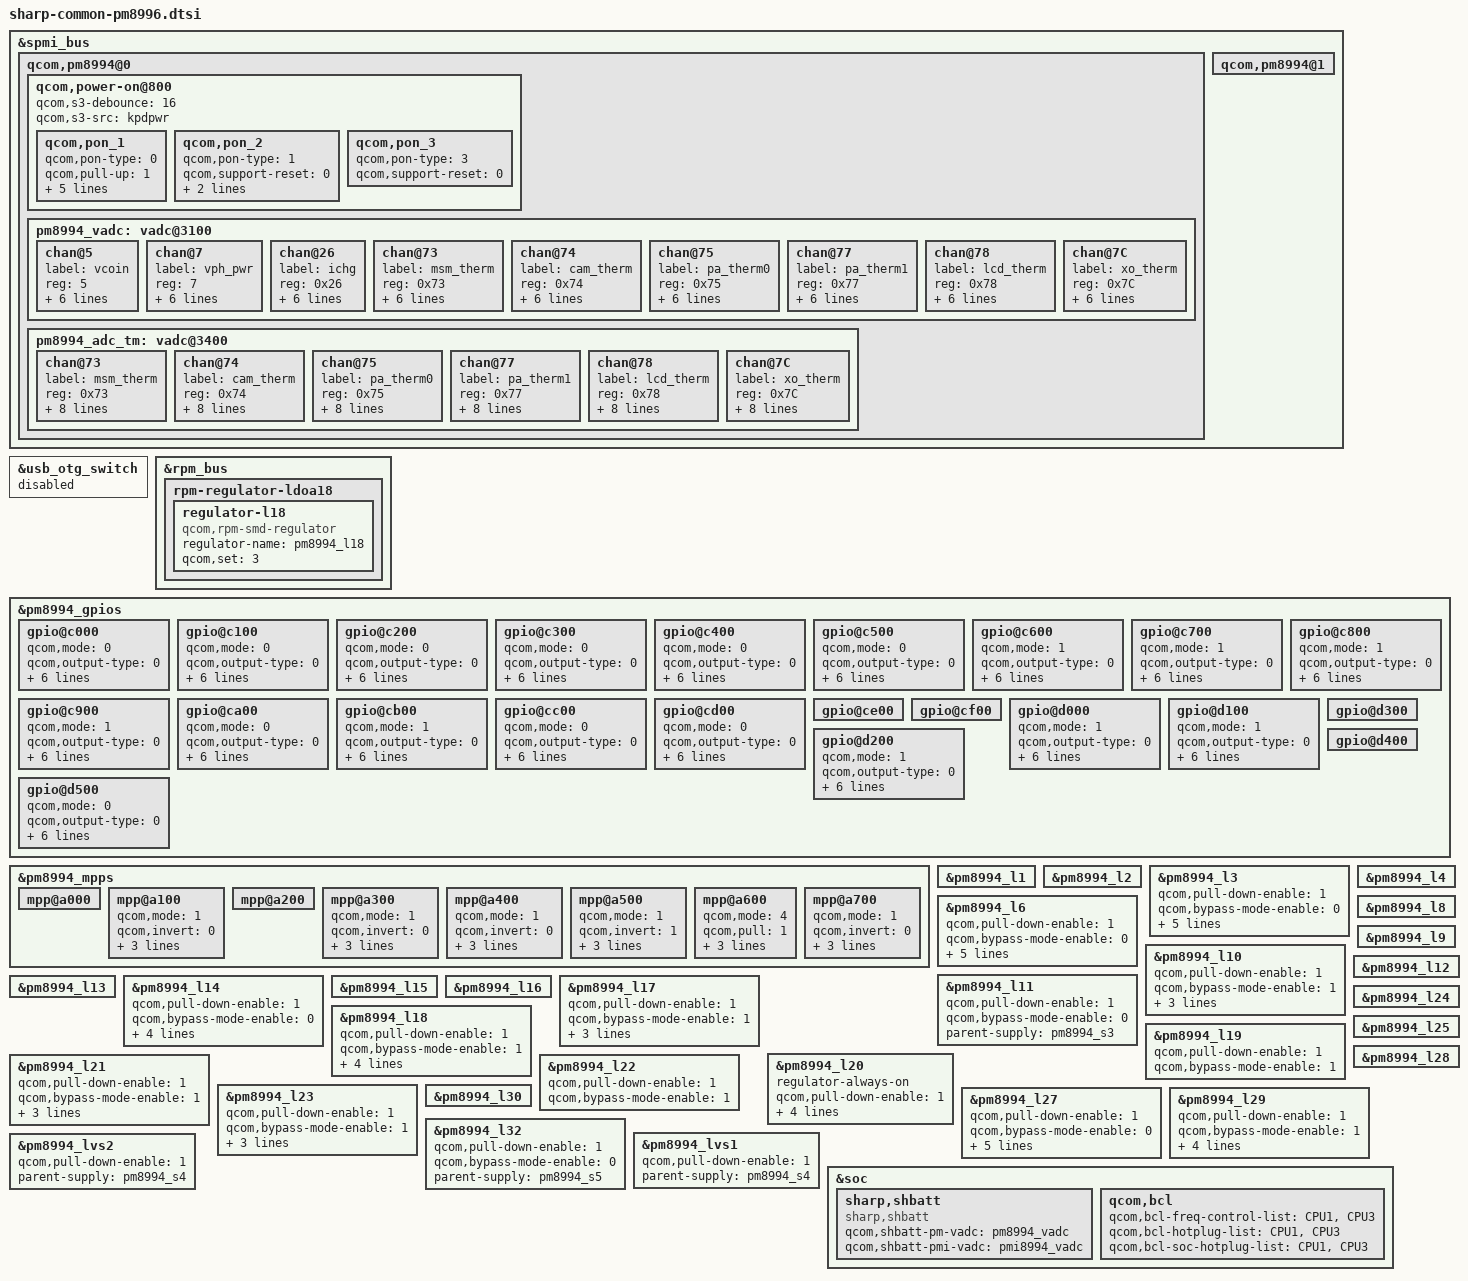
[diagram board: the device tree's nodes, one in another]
/* Copyright (c) 2015, The Linux Foundation. All rights reserved.
 *
 * This program is free software; you can redistribute it and/or modify
 * it under the terms of the GNU General Public License version 2 and
 * only version 2 as published by the Free Software Foundation.
 *
 * This program is distributed in the hope that it will be useful,
 * but WITHOUT ANY WARRANTY; without even the implied warranty of
 * MERCHANTABILITY or FITNESS FOR A PARTICULAR PURPOSE.  See the
 * GNU General Public License for more details.
 */

/*****************************************/
/*  pm8994: qcom,pm8994 alias            */
/*****************************************/

&spmi_bus {
	
	qcom,pm8994@0 {
		qcom,power-on@800 {
			qcom,s3-debounce = <16>;
			qcom,s3-src = "kpdpwr";

			qcom,pon_1 {
				qcom,pon-type = <0>;
				qcom,pull-up = <1>;
				linux,code = <116>;
				qcom,support-reset = <1>;
				qcom,s1-timer = <6720>;
				qcom,s2-timer = <1000>;
				qcom,s2-type = <8>;
			};

			qcom,pon_2 {
				qcom,pon-type = <1>;
//				qcom,support-reset = <1>;
				qcom,support-reset = <0>;
				qcom,pull-up = <1>;
//				qcom,s1-timer = <6720>;
//				qcom,s2-timer = <1000>;
//				qcom,s2-type = <7>;
//				linux,code = <114>;
				linux,code = <115>;
//				qcom,use-bark;
			};

			qcom,pon_3 {
				qcom,pon-type = <3>;
				qcom,support-reset = <0>;
			};
		};
	};

	qcom,pm8994@0 {
		pm8994_vadc: vadc@3100 {
		};
		
		pm8994_adc_tm: vadc@3400 {
		};
	};

	qcom,pm8994@1 {
	};
};

&usb_otg_switch {
	status = "disabled";
};

&rpm_bus {
	rpm-regulator-ldoa18 {
		regulator-l18 {
			compatible = "qcom,rpm-smd-regulator";
			regulator-name = "pm8994_l18";
			qcom,set = <3>;
			/delete-property/ qcom,enable-with-pin-ctrl;
		};
	};
};

/*****************************************/
/*  pm8994-gpios: qpnp-pin               */
/*****************************************/

&pm8994_gpios {

	gpio@c000 { /* GPIO_01 */
		/* Unused */
		qcom,mode = <0>;			/* DIG_IN */
		qcom,output-type = <0>;		/* CMOS */
		qcom,invert = <0>;			/* DISABLE */
		qcom,pull = <4>;			/* PULL_DN */
		qcom,vin-sel = <2>;			/* S4 */
		qcom,out-strength = <1>;	/* LOW */
		qcom,src-sel = <0>;			/* CONSTANT */
		qcom,master-en = <1>;		/* ENABLE */
		status = "okay";
	};

	gpio@c100 { /* GPIO_02 */
		/* Unused */
		qcom,mode = <0>;			/* DIG_IN */
		qcom,output-type = <0>;		/* CMOS */
		qcom,invert = <0>;			/* DISABLE */
		qcom,pull = <4>;			/* PULL_DN */
		qcom,vin-sel = <2>;			/* S4 */
		qcom,out-strength = <1>;	/* LOW */
		qcom,src-sel = <0>;			/* CONSTANT */
		qcom,master-en = <1>;		/* ENABLE */
		status = "okay";
	};

	gpio@c200 { /* GPIO_03 */
		/* Unused */
		qcom,mode = <0>;			/* DIG_IN */
		qcom,output-type = <0>;		/* CMOS */
		qcom,invert = <0>;			/* DISABLE */
		qcom,pull = <4>;			/* PULL_DN */
		qcom,vin-sel = <2>;			/* S4 */
		qcom,out-strength = <1>;	/* LOW */
		qcom,src-sel = <0>;			/* CONSTANT */
		qcom,master-en = <1>;		/* ENABLE */
		status = "okay";
	};

	gpio@c300 { /* GPIO_04 */
		/* DOWN_KEY */
		qcom,mode = <0>;			/* DIG_IN */
		qcom,output-type = <0>;		/* CMOS */
		qcom,invert = <1>;			/* ENABLE */
		qcom,pull = <0>;			/* PULL_UP_30 */
		qcom,vin-sel = <2>;			/* S4 */
		qcom,out-strength = <1>;	/* LOW */
		qcom,src-sel = <0>;			/* CONSTANT */
		qcom,master-en = <1>;		/* ENABLE */
		status = "okay";
	};

	gpio@c400 { /* GPIO_05 */
		/* Unused */
		qcom,mode = <0>;			/* DIG_IN */
		qcom,output-type = <0>;		/* CMOS */
		qcom,invert = <0>;			/* DISABLE */
		qcom,pull = <4>;			/* PULL_DN */
		qcom,vin-sel = <2>;			/* S4 */
		qcom,out-strength = <1>;	/* LOW */
		qcom,src-sel = <0>;			/* CONSTANT */
		qcom,master-en = <1>;		/* ENABLE */
		status = "okay";
	};

	gpio@c500 { /* GPIO_06 */
		/* Unused */
		qcom,mode = <0>;			/* DIG_IN */
		qcom,output-type = <0>;		/* CMOS */
		qcom,invert = <0>;			/* DISABLE */
		qcom,pull = <4>;			/* PULL_DN */
		qcom,vin-sel = <2>;			/* S4 */
		qcom,out-strength = <1>;	/* LOW */
		qcom,src-sel = <0>;			/* CONSTANT */
		qcom,master-en = <1>;		/* ENABLE */
		status = "okay";
	};

	gpio@c600 { /* GPIO_07 */
		/* SD_POW_EN */
		qcom,mode = <1>;			/* DIG_OUT */
		qcom,output-type = <0>;		/* CMOS */
		qcom,invert = <0>;			/* DISABLE */
		qcom,pull = <5>;			/* NO_PULL */
		qcom,vin-sel = <2>;			/* S4 */
		qcom,out-strength = <1>;	/* LOW */
		qcom,src-sel = <0>;			/* CONSTANT */
		qcom,master-en = <1>;		/* ENABLE */
		status = "okay";
	};

	gpio@c700 { /* GPIO_08 */
		/* WLAN_EN */
		/* O/NP/L/0 */
		qcom,mode = <1>;			/* DIG_OUT */
		qcom,output-type = <0>;		/* CMOS */
		qcom,invert = <0>;			/* DISABLE */
		qcom,pull = <5>;			/* NO_PULL */
		qcom,vin-sel = <2>;			/* S4 */
		qcom,out-strength = <1>;	/* LOW */
		qcom,src-sel = <0>;			/* CONSTANT */
		qcom,master-en = <1>;		/* ENABLE */
		status = "okay";
	};

	gpio@c800 { /* GPIO_09 */
		/* WLAN_LDO_3V_CNTRL */
		/* O/NP/L/0 */
		qcom,mode = <1>;			/* DIG_OUT */
		qcom,output-type = <0>;		/* CMOS */
		qcom,invert = <0>;			/* DISABLE */
		qcom,pull = <5>;			/* NO_PULL */
		qcom,vin-sel = <2>;			/* S4 */
		qcom,out-strength = <1>;	/* LOW */
		qcom,src-sel = <0>;			/* CONSTANT */
		qcom,master-en = <1>;		/* ENABLE */
		status = "okay";
	};

	gpio@c900 { /* GPIO_10 */
		/* GRIP_PU */
		qcom,mode = <1>;			/* DIG_OUT */
		qcom,output-type = <0>;		/* CMOS */
		qcom,invert = <0>;			/* DISABLE */
		qcom,pull = <5>;			/* NO_PULL */
		qcom,vin-sel = <2>;			/* S4 */
		qcom,out-strength = <3>;	/* HIGH */
		qcom,src-sel = <0>;			/* CONSTANT */
		qcom,master-en = <1>;		/* ENABLE */
		status = "okay";
	};

	gpio@ca00 { /* GPIO_11 */
		/* Unused */
		qcom,mode = <0>;			/* DIG_IN */
		qcom,output-type = <0>;		/* CMOS */
		qcom,invert = <0>;			/* DISABLE */
		qcom,pull = <4>;			/* PULL_DN */
		qcom,vin-sel = <2>;			/* S4 */
		qcom,out-strength = <1>;	/* LOW */
		qcom,src-sel = <0>;			/* CONSTANT */
		qcom,master-en = <1>;		/* ENABLE */
		status = "okay";
	};

	gpio@cb00 { /* GPIO_12 */
		/* GRIP_RST */
		qcom,mode = <1>;			/* DIG_OUT */
		qcom,output-type = <0>;		/* CMOS */
		qcom,invert = <1>;			/* ENABLE */
		qcom,pull = <5>;			/* NO_PULL */
		qcom,vin-sel = <2>;			/* S4 */
		qcom,out-strength = <1>;	/* LOW */
		qcom,src-sel = <0>;			/* CONSTANT */
		qcom,master-en = <1>;		/* ENABLE */
		status = "okay";
	};

	gpio@cc00 { /* GPIO_13 */
		/* Unused */
		qcom,mode = <0>;			/* DIG_IN */
		qcom,output-type = <0>;		/* CMOS */
		qcom,invert = <0>;			/* DISABLE */
		qcom,pull = <4>;			/* PULL_DN */
		qcom,vin-sel = <2>;			/* S4 */
		qcom,out-strength = <1>;	/* LOW */
		qcom,src-sel = <0>;			/* CONSTANT */
		qcom,master-en = <1>;		/* ENABLE */
		status = "okay";
	};

	gpio@cd00 { /* GPIO_14 */
		/* Unused */
		qcom,mode = <0>;			/* DIG_IN */
		qcom,output-type = <0>;		/* CMOS */
		qcom,invert = <0>;			/* DISABLE */
		qcom,pull = <4>;			/* PULL_DN */
		qcom,vin-sel = <2>;			/* S4 */
		qcom,out-strength = <1>;	/* LOW */
		qcom,src-sel = <0>;			/* CONSTANT */
		qcom,master-en = <1>;		/* ENABLE */
		status = "okay";
	};

	gpio@ce00 { /* GPIO_15 */
		/* DIVCLK1_CDC */
		/* Qualcomm Settings */
	};

	gpio@cf00 { /* GPIO_16 */
		/* PMI_CLK */
		/* Qualcomm Settings */
	};

	gpio@d000 { /* GPIO_17 */
		/* SP_CLK */
		qcom,mode = <1>;			/* DIG_OUT */
		qcom,output-type = <0>;		/* CMOS */
		qcom,invert = <0>;			/* DISABLE */
		qcom,pull = <5>;			/* NO_PULL */
		qcom,vin-sel = <2>;			/* S4 */
		qcom,out-strength = <1>;	/* LOW */
		qcom,src-sel = <0>;			/* CONSTANT */
		qcom,master-en = <1>;		/* ENABLE */
		status = "okay";
	};

	gpio@d100 { /* GPIO_18 */
		/* QCA_LF_CLK */
		/* O/NP/L/ */
		qcom,mode = <1>;			/* DIG_OUT */
		qcom,output-type = <0>;		/* CMOS */
		qcom,invert = <0>;			/* DISABLE */
		qcom,pull = <5>;			/* NO_PULL */
		qcom,vin-sel = <2>;			/* S4 */
		qcom,out-strength = <1>;	/* LOW */
		qcom,src-sel = <3>;			/* SLEEP_CLK5*/
		qcom,master-en = <1>;		/* ENABLE */
		status = "okay";
	};

	gpio@d200 { /* GPIO_19 */
		/* BT_EN */
		/* Qualcomm Settings */
// Bluetooth Driver Add-S
		qcom,mode = <1>;			/* DIG_OUT */
		qcom,output-type = <0>;		/* CMOS */
		qcom,invert = <0>;			/* DISABLE */
		qcom,pull = <5>;			/* NO_PULL */
		qcom,vin-sel = <2>;			/* S4 */
		qcom,out-strength = <1>;	/* LOW */
		qcom,src-sel = <0>;			/* CONSTANT */
		qcom,master-en = <1>;		/* ENABLE */
		status = "okay";
// Bluetooth Driver Add-E
	};

	gpio@d300 { /* GPIO_20 */
		/* PMIC_SLB */
		/* Qualcomm Settings */
	};

	gpio@d400 { /* GPIO_21 */
		/* UIM_BATT_ALARM */
		/* Qualcomm Settings */
	};

	gpio@d500 { /* GPIO_22 */
		/* Unused */
		qcom,mode = <0>;			/* DIG_IN */
		qcom,output-type = <0>;		/* CMOS */
		qcom,invert = <0>;			/* DISABLE */
		qcom,pull = <4>;			/* PULL_DN */
		qcom,vin-sel = <2>;			/* S4 */
		qcom,out-strength = <1>;	/* LOW */
		qcom,src-sel = <0>;			/* CONSTANT */
		qcom,master-en = <1>;		/* ENABLE */
		status = "okay";
	};
};

/*****************************************/
/*  pm8994-mpps: qpnp-pin                */
/*****************************************/

&pm8994_mpps {

	mpp@a000 { /* MPP_01 */
		/* VREF_SDC_UIM_APC */
		/* Qualcomm Settings */
	};

	mpp@a100 { /* MPP_02 */
		/* Unused */
		qcom,mode = <1>;		/* DIG_OUT */
		qcom,invert = <0>;		/* DISABLE */
		qcom,vin-sel = <2>;		/* S4 */
		qcom,src-sel = <0>;		/* CONSTANT */
		qcom,master-en = <1>;	/* ENABLE */
		status = "okay";
	};

	mpp@a200 { /* MPP_03 */
		/* VREF_DACX */
		/* Qualcomm Settings */
	};

	mpp@a300 { /* MPP_04 */
		/* Unused */
		qcom,mode = <1>;		/* DIG_OUT */
		qcom,invert = <0>;		/* DISABLE */
		qcom,vin-sel = <2>;		/* S4 */
		qcom,src-sel = <0>;		/* CONSTANT */
		qcom,master-en = <1>;	/* ENABLE */
		status = "okay";
	};

	mpp@a400 { /* MPP_05 */
		/* Unused */
		qcom,mode = <1>;		/* DIG_OUT */
		qcom,invert = <0>;		/* DISABLE */
		qcom,vin-sel = <2>;		/* S4 */
		qcom,src-sel = <0>;		/* CONSTANT */
		qcom,master-en = <1>;	/* ENABLE */
		status = "okay";
	};

	mpp@a500 { /* MPP_06 */
		/* Unused */
		qcom,mode = <1>;		/* DIG_OUT */
		qcom,invert = <1>;		/* ENABLE */
		qcom,vin-sel = <2>;		/* S4 */
		qcom,src-sel = <0>;		/* CONSTANT */
		qcom,master-en = <1>;	/* ENABLE */
		status = "okay";
	};

	mpp@a600 { /* MPP_07 */
		/* VDIR_CHG */
		qcom,mode = <4>;		/* Analog Input */
		qcom,pull = <1>;		/* QPNP_PIN_MPP_PULL_UP_OPEN */
		qcom,src-sel = <0>;		/* CONSTANT */
		qcom,ain-route = <2>;	/* QPNP_PIN_AIN_AMUX_CH7 */
		qcom,master-en = <1>;	/* ENABLE */
		status = "okay";
	};

	mpp@a700 { /* MPP_08 */
		/* Unused */
		qcom,mode = <1>;		/* DIG_OUT */
		qcom,invert = <0>;		/* DISABLE */
		qcom,vin-sel = <2>;		/* S4 */
		qcom,src-sel = <0>;		/* CONSTANT */
		qcom,master-en = <1>;	/* ENABLE */
		status = "okay";
	};
};
/*****************************************/
/*  pm8994: rpm-regulator                */
/*****************************************/
&pm8994_l1 { /* 8994_l1 */
};

&pm8994_l2 { /* 8994_l2 */
};

&pm8994_l3 { /* 8994_l3 */
//	regulator-always-on;
	qcom,pull-down-enable = <1>;
//	qcom,auto-mode-enable = <0>;
	qcom,bypass-mode-enable = <0>;
	regulator-min-microvolt = <1050000>;
	regulator-max-microvolt = <1050000>;
	qcom,init-voltage = <1050000>;
	parent-supply = <&pm8994_s3>;
	qcom,init-ldo-mode = <1>;
	status = "okay";
};

&pm8994_l4 { /* 8994_l4 */
};

//&pm8994_l5 { /* 8994_l5 not found*/
//};

&pm8994_l6 { /* 8994_l6 */
//	regulator-always-on;
	qcom,pull-down-enable = <1>;
//	qcom,auto-mode-enable = <0>;
	qcom,bypass-mode-enable = <0>;
	regulator-min-microvolt = <1800000>;
	regulator-max-microvolt = <1800000>;
	qcom,init-voltage = <1800000>;
	qcom,init-pin-ctrl-mode = <16>;
	parent-supply = <&pm8994_s5>;
	status = "okay";
};

//&pm8994_l7 { /* 8994_l7 not found*/
//};

&pm8994_l8 { /* 8994_l8 */
};

&pm8994_l9 { /* 8994_l9 */
};

&pm8994_l10 { /* 8994_l10 */
//	regulator-always-on;
	qcom,pull-down-enable = <1>;
//	qcom,auto-mode-enable = <0>;
	qcom,bypass-mode-enable = <1>;
	regulator-min-microvolt = <1800000>;
	regulator-max-microvolt = <1800000>;
	qcom,init-voltage = <1800000>;
	status = "okay";
};

&pm8994_l11 { /* 8994_l11 */
//	regulator-always-on;
	qcom,pull-down-enable = <1>;
//	qcom,auto-mode-enable = <0>;
	qcom,bypass-mode-enable = <0>;
//	regulator-min-microvolt = <1050000>;
//	regulator-max-microvolt = <1050000>;
//	qcom,init-voltage = <1050000>;
	parent-supply = <&pm8994_s3>;
	status = "okay";
};

&pm8994_l12 { /* 8994_l12 */
};

&pm8994_l13 { /* 8994_l13 */
};

&pm8994_l14 { /* 8994_l14 */
//	regulator-always-on;
	qcom,pull-down-enable = <1>;
//	qcom,auto-mode-enable = <0>;
	qcom,bypass-mode-enable = <0>;
	regulator-min-microvolt = <1800000>;
	regulator-max-microvolt = <1800000>;
	qcom,init-voltage = <1800000>;
	parent-supply = <&pm8994_s5>;
	status = "okay";
};

&pm8994_l15 { /* 8994_l15 */
};

&pm8994_l16 { /* 8994_l16 */
};

&pm8994_l17 { /* 8994_l17 */
//	regulator-always-on;
	qcom,pull-down-enable = <1>;
//	qcom,auto-mode-enable = <0>;
	qcom,bypass-mode-enable = <1>;
	regulator-min-microvolt = <2800000>;
	regulator-max-microvolt = <2800000>;
	qcom,init-voltage = <2800000>;
	status = "okay";
};

&pm8994_l18 { /* 8994_l18 */
//	regulator-always-on;
	qcom,pull-down-enable = <1>;
//	qcom,auto-mode-enable = <0>;
	qcom,bypass-mode-enable = <1>;
	regulator-min-microvolt = <2800000>;
	regulator-max-microvolt = <2800000>;
	qcom,init-voltage = <2800000>;
	qcom,init-ldo-mode = <1>;
	status = "okay";
};

&pm8994_l19 { /* 8994_l19 */
//	regulator-always-on;
	qcom,pull-down-enable = <1>;
//	qcom,auto-mode-enable = <0>;
	qcom,bypass-mode-enable = <1>;
//	regulator-min-microvolt = <2800000>;
//	regulator-max-microvolt = <2800000>;
//	qcom,init-voltage = <2800000>;
	status = "okay";
};

&pm8994_l20 { /* 8994_l20 */
	regulator-always-on;
	qcom,pull-down-enable = <1>;
//	qcom,auto-mode-enable = <0>;
	qcom,bypass-mode-enable = <1>;
	regulator-min-microvolt = <2950000>;
	regulator-max-microvolt = <2950000>;
	qcom,init-voltage = <29500000>;
	status = "okay";
};

&pm8994_l21 { /* 8994_l21 */
//	regulator-always-on;
	qcom,pull-down-enable = <1>;
//	qcom,auto-mode-enable = <0>;
	qcom,bypass-mode-enable = <1>;
	regulator-min-microvolt = <2950000>;
	regulator-max-microvolt = <2950000>;
	qcom,init-voltage = <2950000>;
	status = "okay";
};

&pm8994_l22 { /* 8994_l22 */
//	regulator-always-on;
	qcom,pull-down-enable = <1>;
//	qcom,auto-mode-enable = <0>;
	qcom,bypass-mode-enable = <1>;
//	regulator-min-microvolt = <3300000>;
//	regulator-max-microvolt = <3300000>;
//	qcom,init-voltage = <3300000>;
	status = "okay";
};

&pm8994_l23 { /* 8994_l23 */
//	regulator-always-on;
	qcom,pull-down-enable = <1>;
//	qcom,auto-mode-enable = <0>;
	qcom,bypass-mode-enable = <1>;
	regulator-min-microvolt = <3000000>;
	regulator-max-microvolt = <3000000>;
	qcom,init-voltage = <3000000>;
	status = "okay";
};

&pm8994_l24 { /* 8994_l24 */
};

&pm8994_l25 { /* 8994_l25 */
};

//&pm8994_l26 { /* 8994_l26 */
//};

&pm8994_l27 { /* 8994_l27 */
//	regulator-always-on;
	qcom,pull-down-enable = <1>;
//	qcom,auto-mode-enable = <0>;
	qcom,bypass-mode-enable = <0>;
	regulator-min-microvolt = <1050000>;
	regulator-max-microvolt = <1200000>;
	qcom,init-voltage = <1050000>;
	parent-supply = <&pm8994_s3>;
	qcom,init-ldo-mode = <1>;
	status = "okay";
};

&pm8994_l28 { /* 8994_l28 */
};

&pm8994_l29 { /* 8994_l29 */
//	regulator-always-on;
	qcom,pull-down-enable = <1>;
//	qcom,auto-mode-enable = <0>;
	qcom,bypass-mode-enable = <1>;
	regulator-min-microvolt = <2900000>;
	regulator-max-microvolt = <2900000>;
	qcom,init-voltage = <2900000>;
	qcom,init-ldo-mode = <1>;
	status = "okay";
};

&pm8994_l30 { /* 8994_l30 */
};

//&pm8994_l31 { /* 8994_l31 */
//};

&pm8994_l32 { /* 8994_l32 */
//	regulator-always-on;
	qcom,pull-down-enable = <1>;
//	qcom,auto-mode-enable = <0>;
	qcom,bypass-mode-enable = <0>;
//	regulator-min-microvolt = <1800000>;
//	regulator-max-microvolt = <1800000>;
//	qcom,init-voltage = <1800000>;
	parent-supply = <&pm8994_s5>;
	status = "okay";
};

&pm8994_lvs1 { /* 8994_lvs1 */
//	regulator-always-on;
	qcom,pull-down-enable = <1>;
//	qcom,auto-mode-enable = <0>;
	parent-supply = <&pm8994_s4>;
	status = "okay";
};

&pm8994_lvs2 { /* 8994_lvs2 */
//	regulator-always-on;
	qcom,pull-down-enable = <1>;
//	qcom,auto-mode-enable = <0>;
	parent-supply = <&pm8994_s4>;
	status = "okay";
};

/*****************************************/
/*  qpnp-adc-voltage                     */
/*****************************************/

&pm8994_vadc {
	chan@5 {
		label = "vcoin";
		reg = <5>;
		qcom,decimation = <0>;
		qcom,pre-div-channel-scaling = <1>;
		qcom,calibration-type = "absolute";
		qcom,scale-function = <0>;
		qcom,hw-settle-time = <0>;
		qcom,fast-avg-setup = <0>;
	};

	chan@7 {
		label = "vph_pwr";
		reg = <7>;
		qcom,decimation = <0>;
		qcom,pre-div-channel-scaling = <1>;
		qcom,calibration-type = "absolute";
		qcom,scale-function = <0>;
		qcom,hw-settle-time = <0>;
		qcom,fast-avg-setup = <0>;
	};

	chan@26 { /* mpp7 -> ichg */
		label = "ichg";
		reg = <0x26>;
		qcom,decimation = <0>;
		qcom,pre-div-channel-scaling = <1>;
		qcom,calibration-type = "absolute";
		qcom,scale-function = <0>;
		qcom,hw-settle-time = <2>;
		qcom,fast-avg-setup = <0>;
	};

	chan@73 { /* msm_therm */
		label = "msm_therm";
		reg = <0x73>;
		qcom,decimation = <0>;
		qcom,pre-div-channel-scaling = <0>;
		qcom,calibration-type = "ratiometric";
		qcom,scale-function = <2>;
		qcom,hw-settle-time = <2>;
		qcom,fast-avg-setup = <0>;
	};

	chan@74 { /* emmc_therm -> cam_therm */
		label = "cam_therm";
		reg = <0x74>;
		qcom,decimation = <0>;
		qcom,pre-div-channel-scaling = <0>;
		qcom,calibration-type = "ratiometric";
		qcom,scale-function = <2>;
		qcom,hw-settle-time = <2>;
		qcom,fast-avg-setup = <0>;
	};

	chan@75 { /* pa_therm0 */
		label = "pa_therm0";
		reg = <0x75>;
		qcom,decimation = <0>;
		qcom,pre-div-channel-scaling = <0>;
		qcom,calibration-type = "ratiometric";
		qcom,scale-function = <2>;
		qcom,hw-settle-time = <2>;
		qcom,fast-avg-setup = <0>;
	};

	chan@77 { /* pa_therm1 */
		label = "pa_therm1";
		reg = <0x77>;
		qcom,decimation = <0>;
		qcom,pre-div-channel-scaling = <0>;
		qcom,calibration-type = "ratiometric";
		qcom,scale-function = <2>;
		qcom,hw-settle-time = <2>;
		qcom,fast-avg-setup = <0>;
	};

	chan@78 { /* quiet_therm -> lcd_therm */
		label = "lcd_therm";
		reg = <0x78>;
		qcom,decimation = <0>;
		qcom,pre-div-channel-scaling = <0>;
		qcom,calibration-type = "ratiometric";
		qcom,scale-function = <2>;
		qcom,hw-settle-time = <2>;
		qcom,fast-avg-setup = <0>;
	};

	chan@7C { /* xo_therm */
		label = "xo_therm";
		reg = <0x7C>;
		qcom,decimation = <0>;
		qcom,pre-div-channel-scaling = <0>;
		qcom,calibration-type = "ratiometric";
		qcom,scale-function = <4>;
		qcom,hw-settle-time = <5>;
		qcom,fast-avg-setup = <0>;
	};
};


/*****************************************/
/*  qpnp-vadc-tm                         */
/*****************************************/

&pm8994_adc_tm {
	chan@73 { /* msm_therm */
	label = "msm_therm";
		reg = <0x73>;
		qcom,decimation = <0>;
		qcom,pre-div-channel-scaling = <0>;
		qcom,calibration-type = "ratiometric";
		qcom,scale-function = <2>;
		qcom,hw-settle-time = <2>;
		qcom,fast-avg-setup = <0>;
		qcom,btm-channel-number = <0x48>;
		qcom,thermal-node;
	};

	chan@74 { /* emmc_therm -> cam_therm */
		label = "cam_therm";
		reg = <0x74>;
		qcom,decimation = <0>;
		qcom,pre-div-channel-scaling = <0>;
		qcom,calibration-type = "ratiometric";
		qcom,scale-function = <2>;
		qcom,hw-settle-time = <2>;
		qcom,fast-avg-setup = <0>;
		qcom,btm-channel-number = <0x68>;
		qcom,thermal-node;
	};

	chan@75 { /* pa_therm0 */
		label = "pa_therm0";
		reg = <0x75>;
		qcom,decimation = <0>;
		qcom,pre-div-channel-scaling = <0>;
		qcom,calibration-type = "ratiometric";
		qcom,scale-function = <2>;
		qcom,hw-settle-time = <2>;
		qcom,fast-avg-setup = <0>;
		qcom,btm-channel-number = <0x70>;
		qcom,thermal-node;
	};

	chan@77 { /* pa_therm1 */
		label = "pa_therm1";
		reg = <0x77>;
		qcom,decimation = <0>;
		qcom,pre-div-channel-scaling = <0>;
		qcom,calibration-type = "ratiometric";
		qcom,scale-function = <2>;
		qcom,hw-settle-time = <2>;
		qcom,fast-avg-setup = <0>;
		qcom,btm-channel-number = <0x78>;
		qcom,thermal-node;
	};

	chan@78 { /* quiet_therm -> lcd_therm */
		label = "lcd_therm";
		reg = <0x78>;
		qcom,decimation = <0>;
		qcom,pre-div-channel-scaling = <0>;
		qcom,calibration-type = "ratiometric";
		qcom,scale-function = <2>;
		qcom,hw-settle-time = <2>;
		qcom,fast-avg-setup = <0>;
		qcom,btm-channel-number = <0x80>;
		qcom,thermal-node;
	};

	chan@7C { /* xo_therm */
		label = "xo_therm";
		reg = <0x7C>;
		qcom,decimation = <0>;
		qcom,pre-div-channel-scaling = <0>;
		qcom,calibration-type = "ratiometric";
		qcom,scale-function = <4>;
		qcom,hw-settle-time = <5>;
		qcom,fast-avg-setup = <0>;
		qcom,btm-channel-number = <0x88>;
		qcom,thermal-node;
	};
};

/*****************************************/
/*  SHARP Device Drivers                 */
/*****************************************/
&soc {
	/*---------------------------------------*/
	/*  Battery Control Driver               */
	/*---------------------------------------*/
	sharp,shbatt {
		compatible = "sharp,shbatt";
		qcom,shbatt-pm-vadc = <&pm8994_vadc>;
		qcom,shbatt-pmi-vadc = <&pmi8994_vadc>;
		status = "ok";
	};
	
	qcom,bcl {
		qcom,bcl-freq-control-list = <&CPU1 &CPU3>;
		qcom,bcl-hotplug-list = <&CPU1 &CPU3>;
		qcom,bcl-soc-hotplug-list = <&CPU1 &CPU3>;
	};
};
